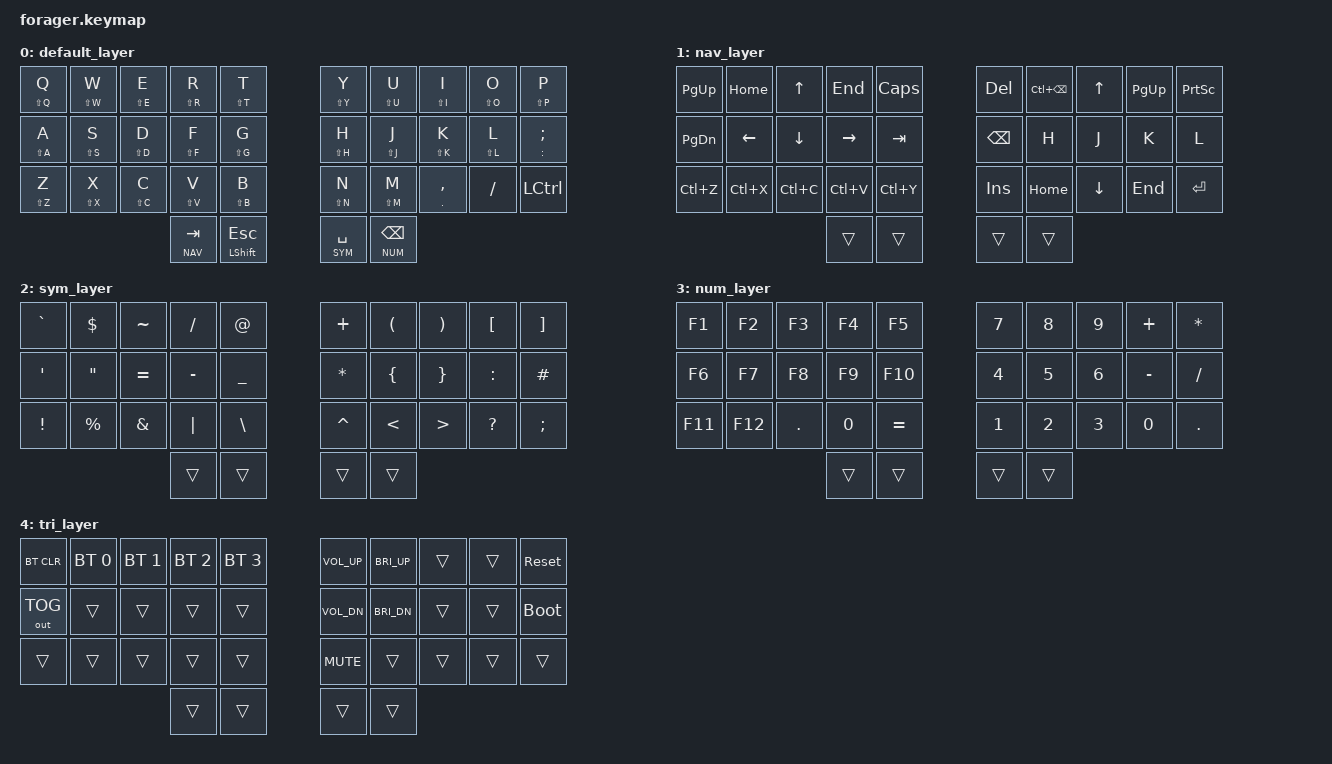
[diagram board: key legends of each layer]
/*
 * Forager Keyboard Layout Config (ZMK Firmware)
 * Features: Tap-for-Lower / Hold-for-Caps, Merged Punctuation, Custom Combos, Vim Navigation
 */

#include <behaviors.dtsi>
#include <dt-bindings/zmk/keys.h>
#include <dt-bindings/zmk/bt.h>
#include <dt-bindings/zmk/outputs.h>

/* Layer Definitions */
#define BASE 0  /* Primary QWERTY typing layer */
#define NAV  1  /* Arrow keys, Vim motion, and editing shortcuts */
#define SYM  2  /* Programming symbols (Python, Bash, Markdown) */
#define NUM  3  /* Numpad and Function keys (F1-F12) */
#define TRI  4  /* System settings (Bluetooth, Brightness, Volume) */

/ {
    /* ------------------------------------------------------------------
     * COMBOS: Pressing two keys simultaneously triggers a third key/action
     * ------------------------------------------------------------------ */
    combos {
        compatible = "zmk,combos";

        /* W + E = '#' (Quick Markdown Headings) */
        combo-hash {
            timeout-ms = <50>;
            key-positions = <1 2>;
            bindings = <&kp HASH>;
        };

        /* J + K = ENTER */
        combo-enter {
            timeout-ms = <50>;
            key-positions = <16 17>;
            bindings = <&kp RET>;
        };

        /* D + F = Word Delete (Ctrl + Backspace) */
        combo-word-del {
            timeout-ms = <50>;
            key-positions = <12 13>;
            bindings = <&kp LC(BSPC)>;
        };
    };

    /* ------------------------------------------------------------------
     * BEHAVIORS: Custom hold-tap rules to squeeze dual functions onto one key
     * ------------------------------------------------------------------ */
    behaviors {
        /* Tap = Semicolon (;), Hold = Colon (:) */
        semi_colon: semi-colon-tap-hold {
            compatible = "zmk,behavior-hold-tap";
            #binding-cells = <2>;
            tapping-term-ms = <170>;
            quick-tap-ms = <125>;
            flavor = "tap-preferred";
            bindings = <&kp>, <&kp>;
        };

        /* Tap = Comma (,), Hold = Period (.) */
        dot_comma: dot-comma-tap-hold {
            compatible = "zmk,behavior-hold-tap";
            #binding-cells = <2>;
            tapping-term-ms = <170>;
            quick-tap-ms = <125>;
            flavor = "tap-preferred";
            bindings = <&kp>, <&kp>;
        };

        /* Tap = Lowercase Letter, Hold = Capital Letter */
        hp: hold-capital {
            compatible = "zmk,behavior-hold-tap";
            #binding-cells = <2>;
            tapping-term-ms = <170>;
            quick-tap-ms = <125>;
            flavor = "tap-preferred";
            bindings = <&kp>, <&kp>;
        };

        /* Left Thumb Outer: Tap = Escape, Hold = Shift */
        shft_esc: shift-escape {
            compatible = "zmk,behavior-hold-tap";
            #binding-cells = <2>;
            tapping-term-ms = <175>;
            quick-tap-ms = <150>;
            flavor = "hold-preferred";
            bindings = <&kp>, <&kp>;
        };
    };

    /* ------------------------------------------------------------------
     * CONDITIONAL LAYERS: Automatically activate Layer 4 (TRI)
     * when both Layer 1 (NAV) and Layer 2 (SYM) are held together
     * ------------------------------------------------------------------ */
    conditional_layers {
        compatible = "zmk,conditional-layers";
        tri-layer {
            if-layers = <NAV SYM>;
            then-layer = <TRI>;
        };
    };

    keymap {
        compatible = "zmk,keymap";

        /* 
         * LAYER 0: DEFAULT BASE LAYER
         */
        default_layer {
            bindings = <
    &hp LS(Q) Q &hp LS(W) W &hp LS(E) E &hp LS(R) R &hp LS(T) T   &hp LS(Y) Y &hp LS(U) U &hp LS(I) I &hp LS(O) O &hp LS(P) P
    &hp LS(A) A &hp LS(S) S &hp LS(D) D &hp LS(F) F &hp LS(G) G   &hp LS(H) H &hp LS(J) J &hp LS(K) K &hp LS(L) L &semi_colon COLON SEMI
    &hp LS(Z) Z &hp LS(X) X &hp LS(C) C &hp LS(V) V &hp LS(B) B   &hp LS(N) N &hp LS(M) M &dot_comma DOT COMMA &kp FSLH &kp LCTRL
                            &lt NAV TAB &shft_esc LSHFT ESC       &lt SYM SPACE &lt NUM BSPC
            >;
        };

        /* 
         * LAYER 1: VIM & NAVIGATION
         */
        nav_layer {
            bindings = <
    &kp PG_UP   &kp HOME    &kp UP      &kp END     &kp CAPS      &kp DEL     &kp LC(BSPC)&kp UP      &kp PG_UP   &kp PSCRN
    &kp PG_DN   &kp LEFT    &kp DOWN    &kp RIGHT   &kp TAB       &kp BSPC    &kp H       &kp J       &kp K       &kp L
    &kp LC(Z)   &kp LC(X)   &kp LC(C)   &kp LC(V)   &kp LC(Y)     &kp INS     &kp HOME    &kp DOWN    &kp END     &kp RET
                            &trans      &trans                    &trans      &trans
            >;
        };

        /* 
         * LAYER 2: SYMBOLS & PROGRAMMING SYNTAX
         */
        sym_layer {
            bindings = <
    &kp GRAVE   &kp DLLR    &kp TILDE   &kp FSLH    &kp AT        &kp PLUS    &kp LPAR    &kp RPAR    &kp LBKT    &kp RBKT
    &kp SQT     &kp DQT     &kp EQUAL   &kp MINUS   &kp UNDER     &kp STAR    &kp LBRC    &kp RBRC    &kp COLON   &kp HASH
    &kp EXCL    &kp PRCNT   &kp AMPS    &kp PIPE    &kp BSLH      &kp CARET   &kp LT      &kp GT      &kp QMARK   &kp SEMI
                            &trans      &trans                    &trans      &trans
            >;
        };

        /* 
         * LAYER 3: NUMBERS & NUMPAD
         */
        num_layer {
            bindings = <
    &kp F1      &kp F2      &kp F3      &kp F4      &kp F5        &kp N7      &kp N8      &kp N9      &kp PLUS    &kp STAR
    &kp F6      &kp F7      &kp F8      &kp F9      &kp F10       &kp N4      &kp N5      &kp N6      &kp MINUS   &kp FSLH
    &kp F11     &kp F12     &kp DOT     &kp N0      &kp EQUAL     &kp N1      &kp N2      &kp N3      &kp N0      &kp DOT
                            &trans      &trans                    &trans      &trans
            >;
        };

        /* 
         * LAYER 4: SYSTEM CONTROLS & HARDWARE
         */
        tri_layer {
            bindings = <
    &bt BT_CLR  &bt BT_SEL 0 &bt BT_SEL 1 &bt BT_SEL 2 &bt BT_SEL 3 &kp C_VOL_UP &kp C_BRI_UP &trans   &trans      &sys_reset
    &out OUT_TOG &trans     &trans      &trans      &trans        &kp C_VOL_DN &kp C_BRI_DN &trans   &trans      &bootloader
    &trans      &trans      &trans      &trans      &trans        &kp C_MUTE   &trans       &trans   &trans      &trans
                            &trans      &trans                    &trans       &trans
            >;
        };
    };
};
